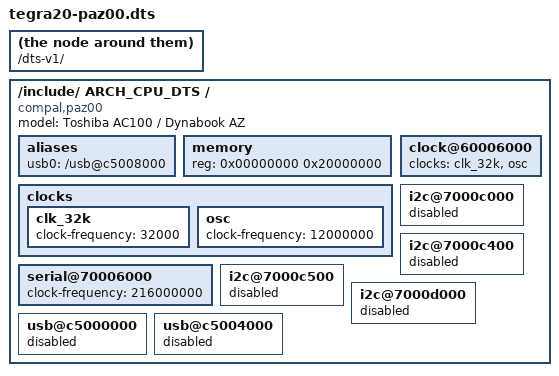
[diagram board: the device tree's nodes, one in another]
/dts-v1/;

/include/ ARCH_CPU_DTS

/ {
        model = "Toshiba AC100 / Dynabook AZ";
        compatible = "compal,paz00", "nvidia,tegra20";

	aliases {
		usb0 = "/usb@c5008000";
	};

	memory {
		reg = <0x00000000 0x20000000>;
	};

	clocks {
		clk_32k: clk_32k {
			clock-frequency = <32000>;
		};
		osc {
			clock-frequency = <12000000>;
		};
	};

	clock@60006000 {
		clocks = <&clk_32k &osc>;
	};

	serial@70006000 {
		clock-frequency = < 216000000 >;
	};

	i2c@7000c000 {
		status = "disabled";
	};

	i2c@7000c400 {
		status = "disabled";
	};

	i2c@7000c500 {
		status = "disabled";
	};

	i2c@7000d000 {
		status = "disabled";
	};

	usb@c5000000 {
		status = "disabled";
	};

	usb@c5004000 {
		status = "disabled";
	};
};
